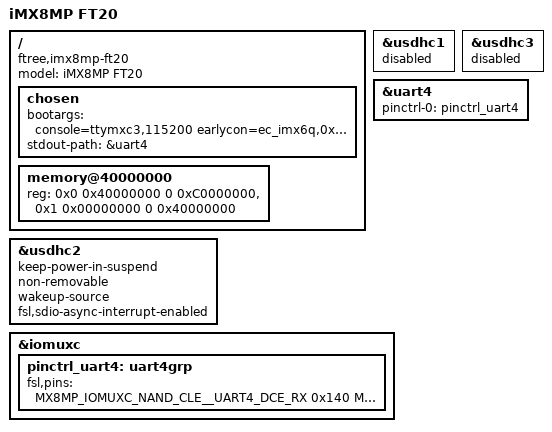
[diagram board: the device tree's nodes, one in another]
// SPDX-License-Identifier: (GPL-2.0+ OR MIT)
/*
 * ftree ft20 minimal u-boot
 */

/dts-v1/;

#include "imx8mp-evk.dts"

/ {
	model = "iMX8MP FT20";

	compatible = "ftree,imx8mp-ft20", "fsl,imx8mp-evk", "fsl,imx8mp";

	chosen {
		bootargs = "console=ttymxc3,115200 earlycon=ec_imx6q,0x30A60000,115200";
		stdout-path = &uart4;
	};

	/* 1 x Micron MT53D1024M32D4DT 2-ch dual-die per channel */

	memory@40000000 {
		device_type = "memory";
		reg = <0x0 0x40000000 0 0xC0000000>,
		      <0x1 0x00000000 0 0x40000000>;
	};
};

&usdhc1 {
	status = "disabled";
};

&usdhc3 {
	status = "disabled";
};

&uart4 {
	/* console */
	pinctrl-names = "default";
	pinctrl-0 = <&pinctrl_uart4>;
	status = "okay";
};

&usdhc2 {
	/delete-property/ cd-gpios;
	keep-power-in-suspend;
	non-removable;
	wakeup-source;
	fsl,sdio-async-interrupt-enabled;
};

&iomuxc {
	pinctrl_uart4: uart4grp {
		fsl,pins = <
			MX8MP_IOMUXC_NAND_CLE__UART4_DCE_RX        0x140
			MX8MP_IOMUXC_NAND_DATA01__UART4_DCE_TX     0x140
	       >;
	};
};
